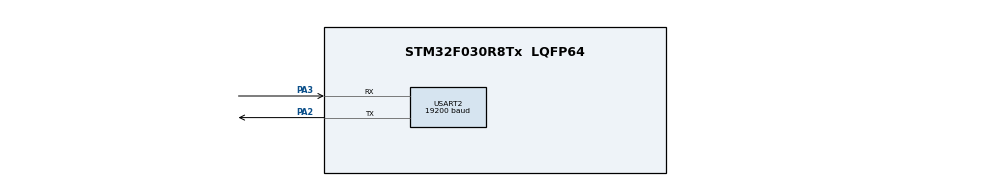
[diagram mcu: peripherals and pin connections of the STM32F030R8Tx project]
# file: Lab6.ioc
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Mcu.Family=STM32F0
Mcu.Name=STM32F030R8Tx
Mcu.Package=LQFP64
NVIC.USART2_IRQn=true\:0\:0\:false
PA2.Mode=Asynchronous
PA2.Signal=USART2_TX
PA3.Mode=Asynchronous
PA3.Signal=USART2_RX
ProjectManager.TargetToolchain=EWARM
USART2.BaudRate=19200
board=Lab6

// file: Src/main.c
/**
  ******************************************************************************
  * File Name          : main.c
  * Description        : Main program body
  ******************************************************************************
  *
  * COPYRIGHT(c) 2015 STMicroelectronics
  *
  * Redistribution and use in source and binary forms, with or without modification,
  * are permitted provided that the following conditions are met:
  *   1. Redistributions of source code must retain the above copyright notice,
  *      this list of conditions and the following disclaimer.
  *   2. Redistributions in binary form must reproduce the above copyright notice,
  *      this list of conditions and the following disclaimer in the documentation
  *      and/or other materials provided with the distribution.
  *   3. Neither the name of STMicroelectronics nor the names of its contributors
  *      may be used to endorse or promote products derived from this software
  *      without specific prior written permission.
  *
  * THIS SOFTWARE IS PROVIDED BY THE COPYRIGHT HOLDERS AND CONTRIBUTORS "AS IS"
  * AND ANY EXPRESS OR IMPLIED WARRANTIES, INCLUDING, BUT NOT LIMITED TO, THE
  * IMPLIED WARRANTIES OF MERCHANTABILITY AND FITNESS FOR A PARTICULAR PURPOSE ARE
  * DISCLAIMED. IN NO EVENT SHALL THE COPYRIGHT HOLDER OR CONTRIBUTORS BE LIABLE
  * FOR ANY DIRECT, INDIRECT, INCIDENTAL, SPECIAL, EXEMPLARY, OR CONSEQUENTIAL
  * DAMAGES (INCLUDING, BUT NOT LIMITED TO, PROCUREMENT OF SUBSTITUTE GOODS OR
  * SERVICES; LOSS OF USE, DATA, OR PROFITS; OR BUSINESS INTERRUPTION) HOWEVER
  * CAUSED AND ON ANY THEORY OF LIABILITY, WHETHER IN CONTRACT, STRICT LIABILITY,
  * OR TORT (INCLUDING NEGLIGENCE OR OTHERWISE) ARISING IN ANY WAY OUT OF THE USE
  * OF THIS SOFTWARE, EVEN IF ADVISED OF THE POSSIBILITY OF SUCH DAMAGE.
  *
  ******************************************************************************
  */
#include "stm32f0xx_hal.h"
#include "usart.h"
#include "gpio.h"

/* USER CODE BEGIN PV */
/* Private variables ---------------------------------------------------------*/

/* USER CODE END PV */

void SystemClock_Config(void);

/* USER CODE BEGIN PFP */
/* Private function prototypes -----------------------------------------------*/

/* USER CODE END PFP */

/* USER CODE BEGIN 0 */
uint8_t tx_buff[]={0x30,0x31,0x32,0x33,0x34,0x35,0x36,0x37,0x38,0x39};
uint8_t rx_buff[10];
/* USER CODE END 0 */

int main(void)
{

  /* MCU Configuration----------------------------------------------------------*/

  /* Reset of all peripherals, Initializes the Flash interface and the Systick. */
  HAL_Init();

  /* Configure the system clock */
  SystemClock_Config();

  /* Initialize all configured peripherals */
  MX_GPIO_Init();
  MX_USART2_UART_Init();

  /* USER CODE BEGIN 2 */
  HAL_UART_Receive_IT(&huart2,rx_buff,10);
  HAL_UART_Transmit_IT(&huart2,tx_buff,10);
  /* USER CODE END 2 */

  /* Infinite loop */
  while (1)
  {

  }

}

/** System Clock Configuration
*/
void SystemClock_Config(void)
{

  RCC_OscInitTypeDef RCC_OscInitStruct;
  RCC_ClkInitTypeDef RCC_ClkInitStruct;

  RCC_OscInitStruct.OscillatorType = RCC_OSCILLATORTYPE_HSI;
  RCC_OscInitStruct.HSIState = RCC_HSI_ON;
  RCC_OscInitStruct.HSICalibrationValue = 16;
  RCC_OscInitStruct.PLL.PLLState = RCC_PLL_NONE;
  HAL_RCC_OscConfig(&RCC_OscInitStruct);

  RCC_ClkInitStruct.ClockType = RCC_CLOCKTYPE_SYSCLK;
  RCC_ClkInitStruct.SYSCLKSource = RCC_SYSCLKSOURCE_HSI;
  RCC_ClkInitStruct.AHBCLKDivider = RCC_SYSCLK_DIV1;
  RCC_ClkInitStruct.APB1CLKDivider = RCC_HCLK_DIV1;
  HAL_RCC_ClockConfig(&RCC_ClkInitStruct, FLASH_LATENCY_0);

  HAL_SYSTICK_Config(HAL_RCC_GetHCLKFreq()/1000);

  HAL_SYSTICK_CLKSourceConfig(SYSTICK_CLKSOURCE_HCLK);

}

/* USER CODE BEGIN 4 */
void HAL_UART_RxCpltCallback(UART_HandleTypeDef *huart)
{
  __NOP();//test if we reach this position
}

void HAL_UART_TxCpltCallback(UART_HandleTypeDef *huart)
{
  __NOP();//test if we reach this position
}

/* USER CODE END 4 */

/************************ (C) COPYRIGHT STMicroelectronics *****END OF FILE****/
